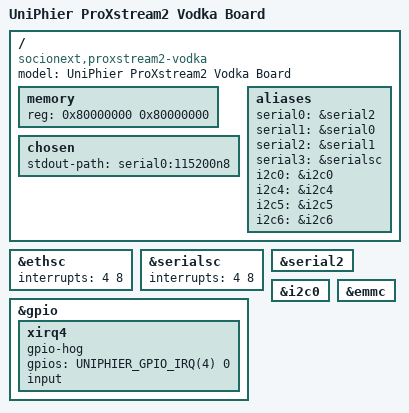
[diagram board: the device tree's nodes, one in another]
// SPDX-License-Identifier: GPL-2.0+ OR MIT
//
// Device Tree Source for UniPhier ProXstream2 Vodka Board
//
// Copyright (C) 2015-2016 Socionext Inc.
//   Author: Masahiro Yamada <yamada.masahiro@socionext.com>

/dts-v1/;
#include "uniphier-proxstream2.dtsi"
#include "uniphier-support-card.dtsi"

/ {
	model = "UniPhier ProXstream2 Vodka Board";
	compatible = "socionext,proxstream2-vodka", "socionext,proxstream2";

	memory {
		device_type = "memory";
		reg = <0x80000000 0x80000000>;
	};

	chosen {
		stdout-path = "serial0:115200n8";
	};

	aliases {
		serial0 = &serial2;
		serial1 = &serial0;
		serial2 = &serial1;
		serial3 = &serialsc;
		i2c0 = &i2c0;
		i2c4 = &i2c4;
		i2c5 = &i2c5;
		i2c6 = &i2c6;
	};
};

&ethsc {
	interrupts = <4 8>;
};

&serialsc {
	interrupts = <4 8>;
};

&serial2 {
	status = "okay";
};

&gpio {
	xirq4 {
		gpio-hog;
		gpios = <UNIPHIER_GPIO_IRQ(4) 0>;
		input;
	};
};

&i2c0 {
	status = "okay";
};

&emmc {
	status = "okay";
};
